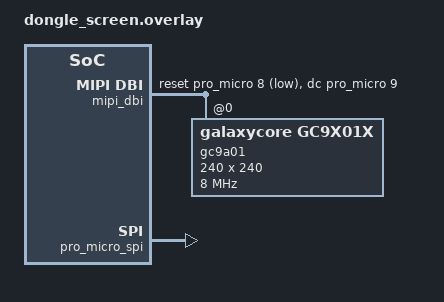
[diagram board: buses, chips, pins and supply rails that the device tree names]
/*
 * GC9A01 240x240 on a nice!nano (pro_micro pin names)
 *   SCL/SCK -> 15   SDA/MOSI -> 16   CS -> 10   DC -> 9   RES -> 8
 *   VCC -> 3V3      GND -> GND       BLK -> 3V3 (always on)
 */
#include <zephyr/dt-bindings/mipi_dbi/mipi_dbi.h>
#include <zephyr/dt-bindings/display/panel.h>

/ {
	chosen {
		zephyr,display = &gc9a01;
	};

	mipi_dbi {
		compatible = "zephyr,mipi-dbi-spi";
		spi-dev = <&pro_micro_spi>;
		dc-gpios = <&pro_micro 9 GPIO_ACTIVE_HIGH>;
		reset-gpios = <&pro_micro 8 GPIO_ACTIVE_LOW>;
		write-only;
		#address-cells = <1>;
		#size-cells = <0>;

		gc9a01: gc9a01@0 {
			compatible = "galaxycore,gc9x01x";
			status = "okay";
			reg = <0>;
			mipi-max-frequency = <8000000>;
			mipi-mode = "MIPI_DBI_MODE_SPI_4WIRE";
			pixel-format = <PANEL_PIXEL_FORMAT_RGB_565>;
			display-inversion;
			width = <240>;
			height = <240>;
		};
	};
};

&pro_micro_spi {
	status = "okay";
	cs-gpios = <&pro_micro 10 GPIO_ACTIVE_LOW>;
};
